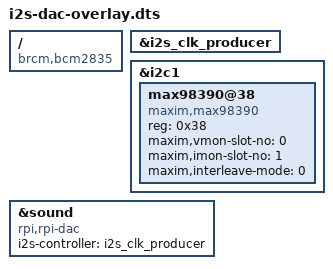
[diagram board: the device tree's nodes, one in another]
// Definitions for RPi DAC
/dts-v1/;
/plugin/;

/ {
	compatible = "brcm,bcm2835";

	fragment@0 {
		target = <&i2s_clk_producer>;
		__overlay__ {
			status = "okay";
		};
	};

	fragment@1 {
		target = <&i2c1>;
		__overlay__ {
			#address-cells = <1>;
			#size-cells = <0>;
			status = "okay";

			max98390@38 {
				#sound-dai-cells = <0>;
				compatible = "maxim,max98390";
				reg = <0x38>;
	                     maxim,vmon-slot-no = <0>;
	                     maxim,imon-slot-no = <1>;
	                     maxim,interleave-mode = <0>;
                status = "okay";
			};
		};

	};

	fragment@2 {
		target = <&sound>;
		__overlay__ {
			compatible = "rpi,rpi-dac";
			i2s-controller = <&i2s_clk_producer>;
			status = "okay";
		};
	};
};
